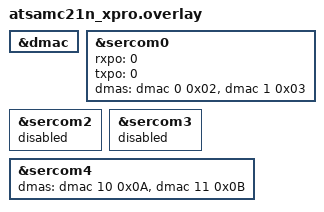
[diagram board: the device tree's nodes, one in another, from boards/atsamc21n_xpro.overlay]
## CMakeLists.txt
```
# SPDX-License-Identifier: Apache-2.0

cmake_minimum_required(VERSION 3.28.0)

find_package(Zephyr REQUIRED HINTS $ENV{ZEPHYR_BASE})
project(uart_high_level_api)

target_sources(app PRIVATE
    src/test_uart_async.c
    )
target_sources_ifdef(CONFIG_UART_WIDE_DATA app PRIVATE src/test_uart_wide.c)
```

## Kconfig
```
# Copyright (c) 2024 STMicroelectronics
#
# SPDX-License-Identifier: Apache-2.0

mainmenu "UART Async Test"

source "Kconfig.zephyr"

if DCACHE

config DT_DEFINED_NOCACHE
	bool "Enable this if a nocache region is defined in devicetree"

if DT_DEFINED_NOCACHE

config DT_DEFINED_NOCACHE_NAME
	string "Name of the nocache region defined in devicetree (uppercase)"

endif # DT_DEFINED_NOCACHE

endif # DCACHE

config TEST_LONG_BUFFER_SIZE
	int "Long buffer size"
	default 1024

config VAR_LENGTH_BUFFER_TEST_BAUDRATE_LIMIT
	int "Above this UART baudrate value, var length buffer testing will be skipped"
	default 230400

config VAR_LENGTH_BUFFER_MAX_SIZE
	int "Max size of uart buffer used for testing. Testing buffer sizes from 1 to this value."
	default 10
```

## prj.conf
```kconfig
CONFIG_SERIAL=y
CONFIG_UART_ASYNC_API=y
CONFIG_UART_USE_RUNTIME_CONFIGURE=y
CONFIG_ZTEST=y
CONFIG_TEST_USERSPACE=y
```

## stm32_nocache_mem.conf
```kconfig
# SPDX-FileCopyrightText: Copyright The Zephyr Project Contributors
# SPDX-License-Identifier: Apache-2.0

CONFIG_TEST_USERSPACE=n
CONFIG_DCACHE=y
CONFIG_NOCACHE_MEMORY=y
```

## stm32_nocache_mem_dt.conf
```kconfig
# SPDX-FileCopyrightText: Copyright The Zephyr Project Contributors
# SPDX-License-Identifier: Apache-2.0

CONFIG_DCACHE=y
CONFIG_DT_DEFINED_NOCACHE=y
CONFIG_DT_DEFINED_NOCACHE_NAME="RAM_NOCACHE"
CONFIG_USERSPACE=n
```

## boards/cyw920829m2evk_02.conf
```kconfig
CONFIG_TEST_USERSPACE=n
CONFIG_DMA=y
```

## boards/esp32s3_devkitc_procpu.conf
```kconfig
CONFIG_DMA=y
CONFIG_TEST_LONG_BUFFER_SIZE=8192
```

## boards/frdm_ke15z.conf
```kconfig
# KE15Z has only 24 KB SRAM. Default TEST_LONG_BUFFER_SIZE=1024 plus
# ~50 test-side buffers + ZTEST framework overflows RAM. Trim to fit.
CONFIG_TEST_LONG_BUFFER_SIZE=128
CONFIG_MAIN_STACK_SIZE=1024
CONFIG_ZTEST_STACK_SIZE=1024
```

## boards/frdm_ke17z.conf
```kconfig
# KE17Z has only 32 KB SRAM. Default TEST_LONG_BUFFER_SIZE=1024 plus
# ~50 test-side buffers + ZTEST framework overflows RAM. Trim to fit.
CONFIG_TEST_LONG_BUFFER_SIZE=256
CONFIG_MAIN_STACK_SIZE=1024
CONFIG_ZTEST_STACK_SIZE=1024
```

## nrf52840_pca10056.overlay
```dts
/* SPDX-License-Identifier: Apache-2.0 */

/ {
	chosen {
		zephyr,console = &uart1;
	};
};

&uart1 {
	current-speed = <115200>;
	status = "ok";
	tx-pin = <6>;
	rx-pin = <8>;
	rts-pin = <0>;
	cts-pin = <0>;
};

&uart0 {
	compatible = "nordic,nrf-uart";
	current-speed = <115200>;
	status = "ok";
	tx-pin = <33>;
	rx-pin = <34>;
	rts-pin = <5>;
	cts-pin = <7>;
};
```

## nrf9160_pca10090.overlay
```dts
/* SPDX-License-Identifier: Apache-2.0 */

&uart1 {
	current-speed = <115200>;
	compatible = "nordic,nrf-uarte";
	status = "ok";
	tx-pin = <10>;
	rx-pin = <11>;
};
```

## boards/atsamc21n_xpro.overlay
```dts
/* SPDX-License-Identifier: Apache-2.0 */

&dmac {
	status = "okay";
};

dut: &sercom0 {
	/* Internally loop-back TX and RX on PAD0 */
	rxpo = <0>;
	txpo = <0>;

	/* Configure DMA channels for async operation */
	dmas = <&dmac 0 0x02>, <&dmac 1 0x03>;
	dma-names = "rx", "tx";
};

&sercom2 {
	status = "disabled";
};

&sercom3 {
	status = "disabled";
};

&sercom4 {
	/* configure DMA channels for async operation */
	dmas = <&dmac 10 0x0A>, <&dmac 11 0x0B>;
	dma-names = "rx", "tx";
};
```

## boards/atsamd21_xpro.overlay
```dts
/* SPDX-License-Identifier: Apache-2.0 */

dut: &sercom1 {
	/* Internally loop-back TX and RX on PAD0 */
	rxpo = <0>;
	txpo = <0>;

	/* Configure DMA channels for async operation */
	dmas = <&dmac 0 3>, <&dmac 1 4>;
	dma-names = "rx", "tx";
};
```

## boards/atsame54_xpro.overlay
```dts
/* SPDX-License-Identifier: Apache-2.0 */

dut: &sercom1 {
	status = "okay";
	compatible = "atmel,sam0-uart";
	current-speed = <115200>;
	#address-cells = <1>;
	#size-cells = <0>;

	/* Internally loop-back TX and RX on PAD0 */
	rxpo = <0>;
	txpo = <0>;

	/* Configure DMA channels for async operation */
	dmas = <&dmac 0 6>, <&dmac 1 7>;
	dma-names = "rx", "tx";
};
```

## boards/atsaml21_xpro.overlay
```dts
/*
 * SPDX-License-Identifier: Apache-2.0
 *
 * Copyright (c) 2021 Argentum Systems Ltd.
 */

&dmac {
	status = "okay";
};

&sercom1 {
	/* internally loop-back Tx and Rx on PAD0 */
	rxpo = <0>;
	txpo = <0>;

	/* configure DMA channels for async operation */
	dmas = <&dmac 0 0x03>, <&dmac 1 0x04>;
	dma-names = "rx", "tx";
};

&sercom3 {
	/* configure DMA channels for async operation */
	dmas = <&dmac 10 0x07>, <&dmac 11 0x08>;
	dma-names = "rx", "tx";
};

&sercom4 {
	status = "disabled";
};
```

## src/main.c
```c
/*
 * Copyright (c) 2019 Nordic Semiconductor ASA
 *
 * SPDX-License-Identifier: Apache-2.0
 */

/**
 * @addtogroup t_driver_uart
 * @{
 * @defgroup t_uart_async test_uart_async
 * @}
 */

#include "test_uart.h"

void test_main(void)
{
	init_test();

#ifdef CONFIG_USERSPACE
	set_permissions();
#endif

	ztest_test_suite(uart_async_test,
			 ztest_unit_test(test_single_read_setup),
			 ztest_user_unit_test(test_single_read),
			 ztest_unit_test(test_multiple_rx_enable_setup),
			 ztest_user_unit_test(test_multiple_rx_enable),
			 ztest_unit_test(test_chained_read_setup),
			 ztest_user_unit_test(test_chained_read),
			 ztest_unit_test(test_double_buffer_setup),
			 ztest_user_unit_test(test_double_buffer),
			 ztest_unit_test(test_read_abort_setup),
			 ztest_user_unit_test(test_read_abort),
			 ztest_unit_test(test_chained_write_setup),
			 ztest_user_unit_test(test_chained_write),
			 ztest_unit_test(test_long_buffers_setup),
			 ztest_user_unit_test(test_long_buffers),
			 ztest_unit_test(test_write_abort_setup),
			 ztest_user_unit_test(test_write_abort),
			 ztest_unit_test(test_forever_timeout_setup),
			 ztest_user_unit_test(test_forever_timeout));
	ztest_run_test_suite(uart_async_test);
}
```

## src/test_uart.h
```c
/*
 * Copyright (c) 2019 Nordic Semiconductor ASA
 *
 * SPDX-License-Identifier: Apache-2.0
 */

/**
 * @file
 * @brief UART cases header file
 *
 * Header file for UART cases
 */

#ifndef __TEST_UART_H__
#define __TEST_UART_H__

#include <zephyr/drivers/uart.h>
#include <zephyr/ztest.h>

/* RX and TX pins have to be connected together*/

#if DT_NODE_EXISTS(DT_NODELABEL(dut))
#define UART_NODE DT_NODELABEL(dut)
#elif defined(CONFIG_SOC_SERIES_ESP32C3)
#define UART_NODE DT_NODELABEL(uart1)
#else
#define UART_NODE DT_CHOSEN(zephyr_console)
#endif

#endif /* __TEST_UART_H__ */
```

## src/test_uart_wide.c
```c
/*
 *  Copyright (c) 2023 Jeroen van Dooren
 *
 * SPDX-License-Identifier: Apache-2.0
 */

#include "test_uart.h"

K_SEM_DEFINE(tx_wide_done, 0, 1);
K_SEM_DEFINE(tx_wide_aborted, 0, 1);
K_SEM_DEFINE(rx_wide_rdy, 0, 1);
K_SEM_DEFINE(rx_wide_buf_released, 0, 1);
K_SEM_DEFINE(rx_wide_disabled, 0, 1);

static ZTEST_BMEM const struct device *const uart_dev =
	DEVICE_DT_GET(UART_NODE);

static void init_test(void)
{
	__ASSERT_NO_MSG(device_is_ready(uart_dev));
	uart_rx_disable(uart_dev);
	uart_tx_abort(uart_dev);
	k_sem_reset(&tx_wide_done);
	k_sem_reset(&tx_wide_aborted);
	k_sem_reset(&rx_wide_rdy);
	k_sem_reset(&rx_wide_buf_released);
	k_sem_reset(&rx_wide_disabled);
}

#ifdef CONFIG_USERSPACE
static void set_permissions(void)
{
	k_thread_access_grant(k_current_get(), &tx_wide_done, &tx_wide_aborted,
			      &rx_wide_rdy, &rx_wide_buf_released, &rx_wide_disabled,
			      uart_dev);
}
#endif

static void uart_async_test_init(void)
{
	init_test();

#ifdef CONFIG_USERSPACE
	set_permissions();
#endif
}

static void test_single_read_callback(const struct device *dev,
			       struct uart_event *evt, void *user_data)
{
	ARG_UNUSED(dev);

	switch (evt->type) {
	case UART_TX_DONE:
		k_sem_give(&tx_wide_done);
		break;
	case UART_TX_ABORTED:
		(*(uint32_t *)user_data)++;
		break;
	case UART_RX_RDY:
		k_sem_give(&rx_wide_rdy);
		break;
	case UART_RX_BUF_RELEASED:
		k_sem_give(&rx_wide_buf_released);
		break;
	case UART_RX_DISABLED:
		k_sem_give(&rx_wide_disabled);
		break;
	default:
		break;
	}
}

ZTEST_BMEM volatile uint32_t tx_wide_aborted_count;

static void *single_read_setup_wide(void)
{
	uart_async_test_init();

	uart_callback_set(uart_dev,
			  test_single_read_callback,
			  (void *) &tx_wide_aborted_count);

	return NULL;
}

ZTEST_USER(uart_async_single_read_wide, test_single_read_wide)
{
	uint16_t rx_buf[10] = {0};

	/* Check also if sending from read only memory (e.g. flash) works. */
	static const uint16_t tx_buf[5] = {0x74, 0x65, 0x73, 0x74, 0x0D};

	zassert_not_equal(memcmp(tx_buf, rx_buf, 5), 0,
			  "Initial buffer check failed");

	uart_rx_enable_u16(uart_dev, rx_buf, 10, 50 * USEC_PER_MSEC);
	zassert_equal(k_sem_take(&rx_wide_rdy, K_MSEC(100)), -EAGAIN,
		      "RX_RDY not expected at this point");

	uart_tx_u16(uart_dev, tx_buf, sizeof(tx_buf)/sizeof(uint16_t), 100 * USEC_PER_MSEC);
	zassert_equal(k_sem_take(&tx_wide_done, K_MSEC(100)), 0, "TX_DONE timeout");
	zassert_equal(k_sem_take(&rx_wide_rdy, K_MSEC(100)), 0, "RX_RDY timeout");
	zassert_equal(k_sem_take(&rx_wide_rdy, K_MSEC(100)), -EAGAIN,
		      "Extra RX_RDY received");

	zassert_equal(memcmp(tx_buf, rx_buf, 5), 0, "Buffers not equal");
	zassert_not_equal(memcmp(tx_buf, rx_buf+5, 5), 0, "Buffers not equal");

	uart_tx_u16(uart_dev, tx_buf, sizeof(tx_buf)/sizeof(uint16_t), 100 * USEC_PER_MSEC);
	zassert_equal(k_sem_take(&tx_wide_done, K_MSEC(100)), 0, "TX_DONE timeout");
	zassert_equal(k_sem_take(&rx_wide_rdy, K_MSEC(100)), 0, "RX_RDY timeout");
	zassert_equal(k_sem_take(&rx_wide_buf_released, K_MSEC(100)),
		      0,
		      "RX_BUF_RELEASED timeout");
	zassert_equal(k_sem_take(&rx_wide_disabled, K_MSEC(1000)), 0,
		      "RX_DISABLED timeout");
	zassert_equal(k_sem_take(&rx_wide_rdy, K_MSEC(100)), -EAGAIN,
		      "Extra RX_RDY received");

	zassert_equal(memcmp(tx_buf, rx_buf+5, 5), 0, "Buffers not equal");
	zassert_equal(tx_wide_aborted_count, 0, "TX aborted triggered");
}

ZTEST_SUITE(uart_async_single_read_wide, NULL, single_read_setup_wide,
		NULL, NULL, NULL);
```
